# LFMXO5_25 register map
Vendor: Latticsemi.com; Series: LFMXO5; File version: 1.0
Registers are 32-bit, read-write, reset 0x0 unless marked. A register's access mark holds for its fields unless they carry their own. Offsets are from the block's base; [hi:lo] are bit positions; {n}, {i} and the like mark numbered series.

## i3c_m_inst (part 1 of 2)
Base 0x00010400
0x04 CLKDIV — System Clock Divider Register
  [7:0] sys_clk_div — Indicates the clock pulse width of the generated SCL in terms of number of system clock (clk_i) cycles
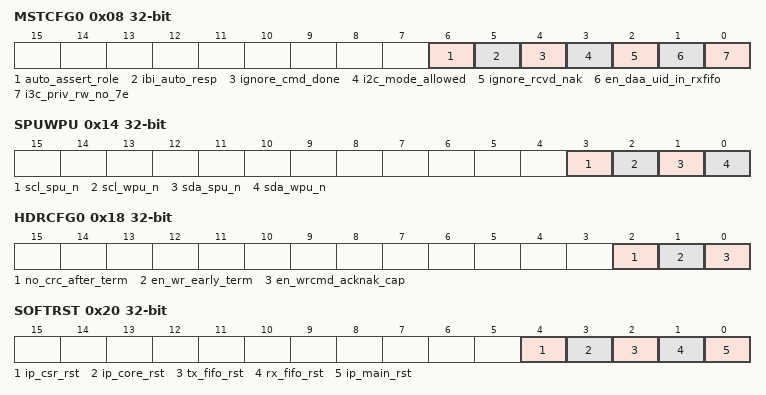
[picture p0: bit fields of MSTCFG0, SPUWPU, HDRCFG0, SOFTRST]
0x08 MSTCFG0 — Controller Configuration 0 Register
  [6] auto_assert_role — Applicable only when Secondary Controller is enabled. 1 - Enable auto assert role. Automatically assert role when taking over as the new Active Controller after GETACCCR CCC. The device will send the broadcast address {0x7E, W} to assert its role. 0 - Disable auto assert role. Device will wait until other device pull the SDA down or if user writes to Tx FIFO.
  [5] ibi_auto_resp — Applicable only when Secondary Controller is enabled. 1 - Always NAK the IBI request and continue the current transfer until Tx FIFO is empty. 0 - Pause the SCL on low during ACK phase and wait for the user to program the appropriate response. See registers ibi_rcnt and ibi_resp.
  [4] ignore_cmd_done — 1 - The I3C controller will continue to process the contents of the Tx FIFO until it is empty. 0 - The I3C controller will stop after transferring 1 packet and the user will have to set/program the start register again to resume the transfer.
  [3] i2c_mode_allowed — 1 - Allows transferring I2C frames. 0 - Only I3C frames can be transferred.
  [2] ignore_rcvd_nak — 1 - The IP will continue to process the contents of the Tx FIFO (until empty) even if a NAK was received. 0 - The I3C controller will stop after receiving a NAK and the user will have to set/program the start register again to resume the transfer.
  [1] en_daa_uid_in_rxfifo — During dynamic address assignment, the I3C targets will broadcast their unique IDs (48bits) including BCR and DCR as part of the arbitration process. 1 - The unique IDs, BCR, and DCR will be stored in Rx FIFO and can be read by user. 0 - It will be discarded.
  [0] i3c_priv_rw_no_7e — 1 - Starts the private write/read access with dynamic address instead of I3C broadcast address 0x7E. 0 - The private access will start with 0x7E address followed by repeated start (Sr) then the target's dynamic address.
0x0C ODTIMER — Open-Drain Timer.
  [3:0] od_timer — Used for generation of SCL clock in open drain mode of I3C transaction. This setting indicates the clock pulse width of open drain SCL clock in terms of number of normal SCL clock cycles as generated using sys_clk_div setting. (0 - 1 SCL clock cycle. Use normal SCL clock generated using the System Clock divider., 1 - 2 SCL clock cycles, ..., 15 - 16 SCL clock cycles)
0x10 I2C_DIV — I2C Clock Divider Register. Applicable only when user enabled the use of internal dividers in IP Generation GUI.
  [7:0] i2c_clkdiv — Used for generation of SCL clock in I2C mode. This setting indicates the clock pulse width of SCL in terms of number of system clock (clk_i) cycles. (0 - 1 clk_i clock cycle, 1 - 2 clk_i clock cycles, ..., 255 - 256 clk_i clock cycles)
0x14 SPUWPU — Pull Up Resistor Disable Register
  [3] scl_spu_n — When set to high, disables the strong pull up resistor in SCL.
  [2] scl_wpu_n — When set to high, disables the weak pull up resistor in SCL.
  [1] sda_spu_n — When set to high, disables the strong pull up resistor in SDA.
  [0] sda_wpu_n — When set to high, disables the weak pull up resistor in SDA.
0x18 HDRCFG0 — HDR-DDR Mode Configuration. Applicable only when user enabled the HDR-DDR capability.
  [2] no_crc_after_term — Applicable only when HDR-DDR capability is enabled. Configures the data transfer ending procedure. 1 - No CRC word follows early termination request. 0 - CRC word follows early termination request.
  [1] en_wr_early_term — Applicable only when HDR-DDR capability is enabled. Configures the data transfer ending procedure. 1 - Enables write early termination request. 0 - Disables write early termination request.
  [0] en_wrcmd_acknak_cap — Applicable only when HDR-DDR capability is enabled. Configures the data transfer ending procedure. 1 - Enables ACK/NAK capability for write command. 0 - Disables ACK/NAK capability for write command.
0x20 SOFTRST — Soft Reset.
  [4] ip_csr_rst — When set to high, resets the IP registers only. Auto-clear.
  [3] ip_core_rst — When set to high, resets the I3C Controller only. Auto-clear.
  [2] tx_fifo_rst — When set to high, resets the Tx FIFO only. Auto-clear.
  [1] rx_fifo_rst — When set to high, resets the Rx FIFO only. Auto-clear.
  [0] ip_main_rst — When set to high, resets the whole IP including registers and FIFO. Auto-clear.
0x44 TXSTART — Transmit Start Register
  [0] tx_start — When set to high, the IP starts processing the contents of Tx FIFO. This register auto-clears when when a command is done or a NAK is received unless it is bypassed by ignore_cmd_done or ignore_rcvd_nak register setting in controller configuration 0 register. To continue with the transfer, user will have to set this to 1 again.
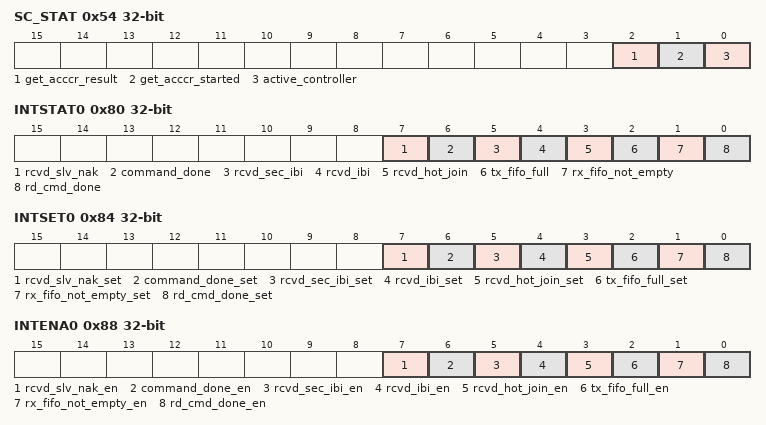
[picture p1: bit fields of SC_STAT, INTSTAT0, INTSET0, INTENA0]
0x54 SC_STAT ro — Secondary Controller Status Info Register. Applicable only when user enabled the Secondary Controller in IP Generation GUI.
  [2] get_acccr_result — This status is the result of the GETACCCR command. This information is valid only if the interrupt status register get_acccr_done is asserted. Clear when interrupt status get_acccr_done is cleared. (0 - Successful controller handoff, 1 - ControllerHandoff failed)
  [1] get_acccr_started — Indicates that the device has started/sent GETACCCR CCC. Clear when interrupt status get_acccr_done is cleared. 1 - Started GETACCCR CCC, 0 - No GETACCCR CCC
  [0] active_controller — Indicates the current role of this device. The default value of this register takes the Device Role GUI parameter setting. If user selected Primary Controller, then the default value will be (1) Active Controller, otherwise it will be acting as a Target (0). The value of this register may change if there is a successful controller handoff or if user forced it by programming the Set Device Role register. 1 - Active Controller 0 - Target
0x58 SC_ROLE ro — Set Device Role register. Applicable only when user enabled the Secondary Controller in IP Generation GUI.
  [2] set_device_role — This status is the result of the GETACCCR command. This information is valid only if the interrupt status register get_acccr_done is asserted. Clear when interrupt status get_acccr_done is cleared. (0 - Successful controller handoff, 1 - ControllerHandoff failed)
0x5C SC_TIMER0 — Secondary Controller Timeout Register. Applicable only when user enabled the Secondary Controller in IP Generation GUI.
  [7:0] crh_timeout0 — Controller role handoff timeout value. This is the number of system clock (clk_i) cycles. The default value is equivalent to 100us (40ns * 2500). This timeout value is used during controller handoff procedure when the former active controller confirms if the new active controller will assert its controller role.
0x60 SC_TIMER1 — Secondary Controller Timeout Register. Applicable only when user enabled the Secondary Controller in IP Generation GUI.
  [7:0] crh_timeout1 — Controller role handoff timeout value. This is the number of system clock (clk_i) cycles. The default value is equivalent to 100us (40ns * 2500). This timeout value is used during controller handoff procedure when the former active controller confirms if the new active controller will assert its controller role.
0x64 SC_TIMER2 — Secondary Controller Timeout Register. Applicable only when user enabled the Secondary Controller in IP Generation GUI.
  [3:0] crh_timeout2 — Controller role handoff timeout value. This is the number of system clock (clk_i) cycles. The default value is equivalent to 100us (40ns * 2500). This timeout value is used during controller handoff procedure when the former active controller confirms if the new active controller will assert its controller role.
0x70 DA_ACKED — Dynamic Address ACKed Counter.
  [7:0] num_da_acked — Running counter that indicates the number of dynamic address that was acknowledged during Enter DAA command. This counter will reset to 0 after writing all 1's.
0x74 IBIRCNT — IBI Read Count Register. Applicable only when in-band interrupt capability is enabled.
  [7:0] ibi_rcnt — Indicates the number of bytes to read from target during IBI. This should be set depending on the target's setting. Set this register to 0 when responding to Hot Join or Secondary Controller interrupt.
0x78 IBIRESP — IBI Response Register. Applicable only when in-band interrupt capability is enabled.
  [0] ibi_resp — This will be the response of the I3C controller to the IBI or Hot Join request. Write to this register will trigger the IP to send the indicated response. 0 - ACK the IBI or Hot Join, 1 - NAK the IBI or Hot Join
0x7C IBIADDR ro — IBI Address Register. Applicable only when in-band interrupt capability is enabled.
  [7:1] ibi_addr — This shows the address of the I3C Target or Secondary Controller that requested the IBI. If the interrupt is Hot Join, this will show the reserved target address 7'h02.
0x80 INTSTAT0 — Interrupt Status 0 Register. When high, it indicates an event and when the corresponding interrupt enable bit is enabled, it will cause the assertion of interrupt port (int_o).
  [7] rcvd_slv_nak — When set to high, it indicates that a NAK was received. Clear on write of 1.
  [6] command_done — When set to high, it indicates that a command has been sent (Private Write/Read or CCC). Clear on write of 1.
  [5] rcvd_sec_ibi — When set, it indicates that Secondary Controller interrupt is received. Clear on write of 1.
  [4] rcvd_ibi — When set, it indicates that In-band interrupt is received. Clear on write of 1.
  [3] rcvd_hot_join — When set to high, it indicates that Hot Join interrupt is received. Clear on write of 1.
  [2] tx_fifo_full — When set to high, it indicates that Tx FIFO is full. Clear on write of 1.
  [1] rx_fifo_not_empty — When set to high, it indicates that Rx FIFO is not empty. Clear on write of 1.
  [0] rd_cmd_done — When set to high, it indicates that a private read is done and all requested data specified by length are available in the Rx FIFO. Clear on write of 1.
0x84 INTSET0 wo — Interrupt Set 0 Register. This is a dummy register that is used to test the assertion of interrupt status. When set to high, it triggers the corresponding interrupt status 0 signal.
  [7] rcvd_slv_nak_set — When set to high, it triggers the corresponding interrupt status 0 signal.
  [6] command_done_set — When set to high, it triggers the corresponding interrupt status 0 signal.
  [5] rcvd_sec_ibi_set — When set to high, it triggers the corresponding interrupt status 0 signal.
  [4] rcvd_ibi_set — When set to high, it triggers the corresponding interrupt status 0 signal.
  [3] rcvd_hot_join_set — When set to high, it triggers the corresponding interrupt status 0 signal.
  [2] tx_fifo_full_set — When set to high, it triggers the corresponding interrupt status 0 signal.
  [1] rx_fifo_not_empty_set — When set to high, it triggers the corresponding interrupt status 0 signal.
  [0] rd_cmd_done_set — When set to high, it triggers the corresponding interrupt status 0 signal.
0x88 INTENA0 — Interrupt Enable 0 Register. When set to high, it enables the corresponding interrupt status 0 signal to cause the assertion of interrupt port signal (int_o).
  [7] rcvd_slv_nak_en — When set to high, it enables the corresponding interrupt status 0 signal to cause the assertion of interrupt port signal (int_o).
  [6] command_done_en — When set to high, it enables the corresponding interrupt status 0 signal to cause the assertion of interrupt port signal (int_o).
  [5] rcvd_sec_ibi_en — When set to high, it enables the corresponding interrupt status 0 signal to cause the assertion of interrupt port signal (int_o).
  [4] rcvd_ibi_en — When set to high, it enables the corresponding interrupt status 0 signal to cause the assertion of interrupt port signal (int_o).
  [3] rcvd_hot_join_en — When set to high, it enables the corresponding interrupt status 0 signal to cause the assertion of interrupt port signal (int_o).
  [2] tx_fifo_full_en — When set to high, it enables the corresponding interrupt status 0 signal to cause the assertion of interrupt port signal (int_o).
  [1] rx_fifo_not_empty_en — When set to high, it enables the corresponding interrupt status 0 signal to cause the assertion of interrupt port signal (int_o).
  [0] rd_cmd_done_en — When set to high, it enables the corresponding interrupt status 0 signal to cause the assertion of interrupt port signal (int_o).
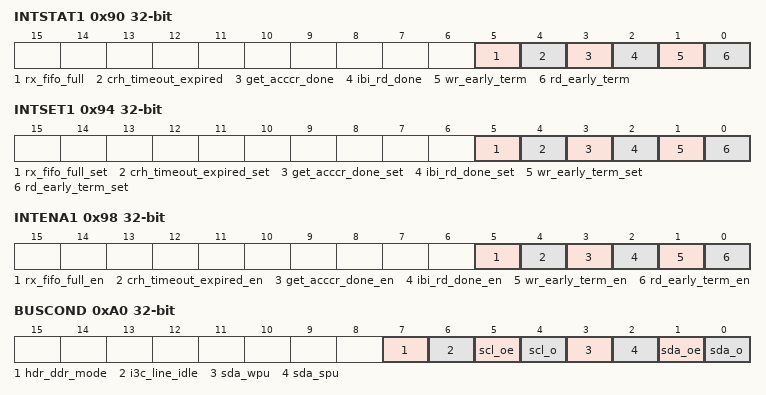
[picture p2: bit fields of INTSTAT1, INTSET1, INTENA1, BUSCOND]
0x90 INTSTAT1 — Interrupt Status 1 Register. When high, it indicates an event and when the corresponding interrupt enable bit is enabled, it will cause the assertion of interrupt port (int_o).
  [5] rx_fifo_full — When set to high, it indicates that Rx FIFO is full. Clear on write of 1.
  [4] crh_timeout_expired — Applicable only when user enabled the Secondary Controller in IP Generation GUI. When set to high, it indicates that the controller handoff has failed due to the new controller failing to assert its role within the specified timeout value in Secondary Controller Timeout register. This means that this device will remain as active controller. Clear on write of 1.
  [3] get_acccr_done — Applicable only when user enabled the Secondary Controller in IP Generation GUI. When set to high, it indicates that GETACCCR CCC was done and the result of this command is available in the secondary controller status info register. Clear on write of 1.
  [2] ibi_rd_done — When set to high, it indicates IBI payload was received and IBI read transaction has been terminated. Clear on write of 1.
  [1] wr_early_term — When set to high, it indicates that I2C private write data was not completely transferred due to the target terminating it with NAK. Clear on write of 1.
  [0] rd_early_term — When set to high, it indicates that a private read is done due to target terminating with T bit==0 and the read data received is less than what was requested. Clear on write of 1.
0x94 INTSET1 wo — Interrupt Set 1 Register. This is a dummy register that is used to test the assertion of interrupt status. When set to high, it triggers the corresponding interrupt status 1 signal.
  [5] rx_fifo_full_set — When set to high, it triggers the corresponding interrupt status 1 signal.
  [4] crh_timeout_expired_set — When set to high, it triggers the corresponding interrupt status 1 signal.
  [3] get_acccr_done_set — When set to high, it triggers the corresponding interrupt status 1 signal.
  [2] ibi_rd_done_set — When set to high, it triggers the corresponding interrupt status 1 signal.
  [1] wr_early_term_set — When set to high, it triggers the corresponding interrupt status 1 signal.
  [0] rd_early_term_set — When set to high, it triggers the corresponding interrupt status 1 signal.
0x98 INTENA1 — Interrupt Enable 1 Register.When set to high, it enables the corresponding interrupt status 0 signal to cause the assertion of interrupt port signal (int_o).
  [5] rx_fifo_full_en — When set to high, it enables the corresponding interrupt status 0 signal to cause the assertion of interrupt port signal (int_o).
  [4] crh_timeout_expired_en — When set to high, it enables the corresponding interrupt status 0 signal to cause the assertion of interrupt port signal (int_o).
  [3] get_acccr_done_en — When set to high, it enables the corresponding interrupt status 0 signal to cause the assertion of interrupt port signal (int_o).
  [2] ibi_rd_done_en — When set to high, it enables the corresponding interrupt status 0 signal to cause the assertion of interrupt port signal (int_o).
  [1] wr_early_term_en — When set to high, it enables the corresponding interrupt status 0 signal to cause the assertion of interrupt port signal (int_o).
  [0] rd_early_term_en — When set to high, it enables the corresponding interrupt status 0 signal to cause the assertion of interrupt port signal (int_o).
0xA0 BUSCOND ro — Bus Condition Debug Register
  [7] hdr_ddr_mode — When high, indicates that the bus is currently in HDR-DDR mode. Otherwise it is in SDR mode.
  [6] i3c_line_idle — When high, indicates that the bus state is in idle. This also implies that bus is free (SCL and SDA are both high).
  [5] scl_oe — Shows the current value of the SCL output enable. 1 - SCL output is driven, 0 - SCL output is not driven
  [4] scl_o — Shows the current value of the SCL output generated by IP. 1 - SCL output is driven, 0 - SCL output is not driven
  [3] sda_wpu — Shows the current value of the SDA weak pull up control signal. 1 - weak pull up resistor is disabled, 0 - weak pull up resistor is enabled
  [2] sda_spu — Shows the current value of the SDA strong pull up control signal. 1 - strong pull up resistor is disabled, 0 - strong pull up resistor is enabled
  [1] sda_oe — Shows the current value of the SDA output enable. 1 - SDA output is driven, 0 - SDA output is not driven
  [0] sda_o — Shows the current value of the SDA output generated by IP.
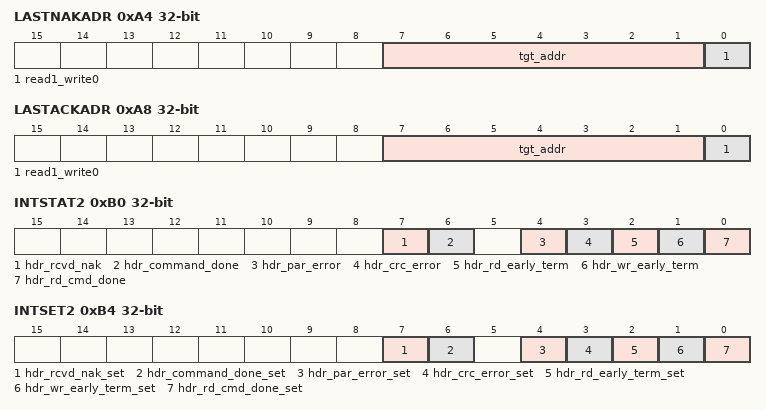
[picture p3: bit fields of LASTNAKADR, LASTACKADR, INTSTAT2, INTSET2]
0xA4 LASTNAKADR — Last NAKed Target Address
  [7:1] tgt_addr — This shows the latest target address driven by the I3C Controller that receives a NAK response.
  [0] read1_write0 — Indicates the transaction type either read (1) or write (0).
0xA8 LASTACKADR — Last ACKed Target Address
  [7:1] tgt_addr — This shows the latest target address driven by the I3C Controller that receives an ACK response.
  [0] read1_write0 — Indicates the transaction type either read (1) or write (0).
0xB0 INTSTAT2 — Interrupt Status 2 Register. When high, it indicates an event and when the corresponding interrupt enable bit is enabled, it will cause the assertion of interrupt port (int_o).
  [7] hdr_rcvd_nak — Applicable only if HDR-DDR capable. When set to high, it indicates that a NAK was received. Clear on write of 1.
  [6] hdr_command_done — Applicable only if HDR-DDR capable. When set to high, it indicates that a command has been sent (HDR Write/Read or CCC). Clear on write of 1.
  [4] hdr_par_error — Applicable only if HDR-DDR capable. When set, it indicates that Parity error is detected. Clear on write of 1.
  [3] hdr_crc_error — Applicable only if HDR-DDR capable. When set, it indicates that CRC error is detected. Clear on write of 1.
  [2] hdr_rd_early_term — Applicable only if HDR-DDR capable. When set to high, it indicates that HDR read is done due to target terminating the transfer and the read data received is less than what was requested. Clear on write of 1.
  [1] hdr_wr_early_term — Applicable only if HDR-DDR capable. When set to high, it indicates that HDR write data was not completely transferred due to the target terminating the transfer. Clear on write of 1.
  [0] hdr_rd_cmd_done — Applicable only if HDR-DDR capable. When set to high, it indicates that HDR read command is done and all requested data specified by length are available in the Rx FIFO. Clear on write of 1.
0xB4 INTSET2 wo — Interrupt Set 2 Register. This is a dummy register that is used to test the assertion of interrupt status. When set to high, it triggers the corresponding interrupt status 2 signal.
  [7] hdr_rcvd_nak_set — When set to high, it triggers the corresponding interrupt status 2 signal.
  [6] hdr_command_done_set — When set to high, it triggers the corresponding interrupt status 2 signal.
  [4] hdr_par_error_set — When set to high, it triggers the corresponding interrupt status 2 signal.
  [3] hdr_crc_error_set — When set to high, it triggers the corresponding interrupt status 2 signal.
  [2] hdr_rd_early_term_set — When set to high, it triggers the corresponding interrupt status 2 signal.
  [1] hdr_wr_early_term_set — When set to high, it triggers the corresponding interrupt status 2 signal.
  [0] hdr_rd_cmd_done_set — When set to high, it triggers the corresponding interrupt status 2 signal.
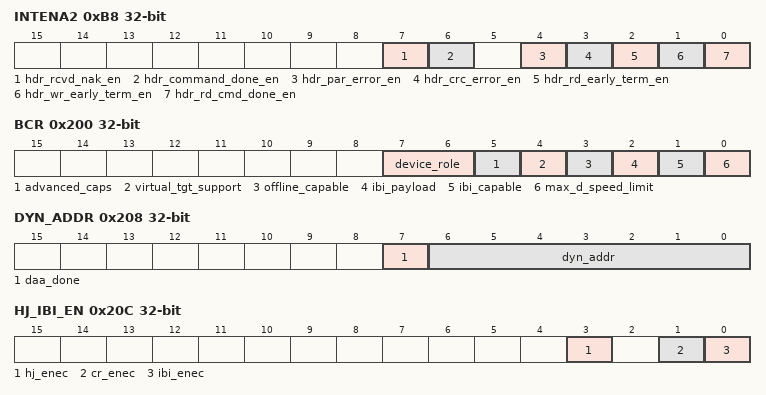
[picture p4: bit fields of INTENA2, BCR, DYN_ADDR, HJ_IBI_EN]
0xB8 INTENA2 — Interrupt Enable 2 Register. When set to high, it enables the corresponding interrupt status 2 signal to cause the assertion of interrupt port signal (int_o).
  [7] hdr_rcvd_nak_en — When set to high, it enables the corresponding interrupt status 2 signal to cause the assertion of interrupt port signal (int_o).
  [6] hdr_command_done_en — When set to high, it enables the corresponding interrupt status 2 signal to cause the assertion of interrupt port signal (int_o).
  [4] hdr_par_error_en — When set to high, it enables the corresponding interrupt status 2 signal to cause the assertion of interrupt port signal (int_o).
  [3] hdr_crc_error_en — When set to high, it enables the corresponding interrupt status 2 signal to cause the assertion of interrupt port signal (int_o).
  [2] hdr_rd_early_term_en — When set to high, it enables the corresponding interrupt status 2 signal to cause the assertion of interrupt port signal (int_o).
  [1] hdr_wr_early_term_en — When set to high, it enables the corresponding interrupt status 2 signal to cause the assertion of interrupt port signal (int_o).
  [0] hdr_rd_cmd_done_en — When set to high, it enables the corresponding interrupt status 2 signal to cause the assertion of interrupt port signal (int_o).
0xC0 TXFIFO — Tx FIFO Access
  [7:0] tx_fifo_data — This is a dummy register that is used to fill data to Tx FIFO. User will use this to send the packet frames to Tx FIFO through repeated write access to this dummy register. Reading this register would return the status of Tx FIFO not_empty flag.
0x100 RXFIFO ro — Rx FIFO Access
  [7:0] rx_fifo_data — This is a dummy register that is used to get the read data from Rx FIFO. The read data as a result of response from read request will be stored in Rx FIFO. User will use this to get the received data from Rx FIFO through repeated read access to this dummy register. User may want to check the interrupt status 0 register (bit[1]) first to determine if Rx FIFO is not empty.
0x200 BCR ro — Target Bus Characteristics Register
  [7:6] device_role — 2'b00 - I3C Target, 2'b01 - I3C Controller-capable (Not implemented in this IP), Others - Reserved for future definition by MIPI Alliance I3C WG
  [5] advanced_caps — 0 - Does not support optional advanced capabilities., 1 - Supports optional advanced capabilities. When Target is configured with IBI capability and IBI payload, this is set to 1 for optional Pending Read MDB support.
  [4] virtual_tgt_support — 0 - Is not a Virtual Target and does not expose other downstream Device(s), 1 - Is a Virtual Target, or exposes other downstream Device(s)
  [3] offline_capable — 0 - Device will always respond to I3C Bus commands, 1 - Device will not always respond to I3C Bus Commands
  [2] ibi_payload — From IBI Payload Size attiribute. 0 - If IBI Payload Size attribute is set to 0. No data bytes follow the IBI., 1 - If IBI Payload Size attribute is set to greater than or equal to 1. One data byte (MDB) shall follow the accepted IBI, and additional data bytes may follow
  [1] ibi_capable — From IBI Capable attribute. 0 - Not capable., 1 - Capable.
  [0] max_d_speed_limit — From Maximum Data Speed Limitation attribute. 0 - No limitation., 1 - With limitation. Controller shall use GETMXDS CCC to get specific limitation from Target.
0x204 DCR ro — Target Device Characteristics Register
  [7:0] dcr — Device ID set by User through DCR attribute. 255 available codes for describing the type of sensor or Device (e.g., accelerometer, gyroscope, composite Devices). Default value is 8'b0 for generic Device.
0x208 DYN_ADDR ro — Assigned dynamic address and done flag
  [7] daa_done — 0 - DA is not yet assigned or is reset by RSTDAA CCC.,1 - DA is assigned via ENTDAA, SETNEWDA, SETAASA or SETDASA CCC
  [6:0] dyn_addr — Dynamic Address Assigned to I3C Target
0x20C HJ_IBI_EN ro — Hot-Join and IBI enable from Controller via ENEC/DISEC CCC
  [3] hj_enec — Hot-Join Enable by Controller. 0 - Target-initiated Hot-Join is not allowed on the I3C bus, 1 - Target-initiated Hot-Join is allowed on the I3C bus
  [1] cr_enec — Controller Role Request Enable by Controller. 0 - Target-initiated Controller Role Request is not allowed on the I3C bus, 1 - Target-initiated Controller Role Request is allowed on the I3C bus
  [0] ibi_enec — IBI Enable by Controller. 0 - Target-initiated interrupts are not allowed on the I3C bus, 1 - Target-initiated interrupts are allowed on the I3C bus
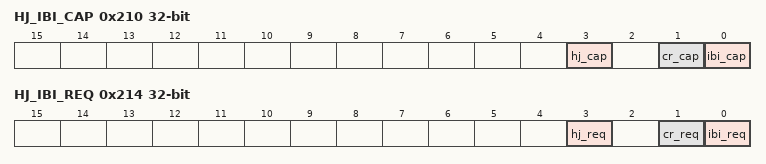
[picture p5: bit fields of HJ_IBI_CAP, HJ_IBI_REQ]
0x210 HJ_IBI_CAP ro — Hot-Join and IBI capability configured by User using attributes
  [3] hj_cap — 0 - Target device is configured without Hot-Join Capability, 1 - Target device is configured with Hot-Join Capability
  [1] cr_cap — 0 - Target device is configured without Secondary-Controller Capability, 1 - Target device is configured with Secondary-Controller Capability
  [0] ibi_cap — 0 - Target device is configured without IBI Capability, 1 - Target device is configured with IBI Capability
0x214 HJ_IBI_REQ — Hot-Join and IBI request from User.
  [3] hj_req — When set to High, Target will initiate Hot-Join request at the next valid opportunity. Reset to 0 when Hot-Join is done or disabled by the Controller.
  [1] cr_req — When set to High, Target will initiate Controller Role Request at the next valid opportunity. Reset to 0 when Controller Role Request is done or disabled by the Controller.
  [0] ibi_req — When set to High, Target will initiate IBI at the next valid opportunity. Reset to 0 when IBI is done or disabled by the Controller.
0x218 HJ_IBI_RETRY — Number of retries for Hot-Join and IBI.
  [7:0] hj_ibi_retry — Indicates number of times the Target retries Hot-Join or IBI when it is NACKed by the Controller. When set to 0, number of tries is not limited.
0x21C MWL_MSB ro — Most significant byte of Maximum Write Length set by the Controller
  [7:0] mwl_msb — Most Significant Byte of maximum write length set by I3C Controller via SETMWL CCC. If SETMWL is greater than default value 512 (FIFO size), MWL will be set to 512.
0x220 MWL_LSB ro — Least significant byte of Maximum Write Length set by the Controller
  [7:0] mwl_lsb — Least Significant Byte of maximum write length set by I3C Controller via SETMWL CCC. If SETMWL is greater than default value 512 (FIFO size), MWL will be set to 512.
0x224 MRL_MSB ro — Most significant byte of Maximum Read Length set by the Controller
  [7:0] mrl_msb — Most Significant Byte of maximum read length set by I3C Controller via SETMRL CCC. If SETMRL is greater than default value 512 (FIFO size), MRL will be set to 512.
0x228 MRL_LSB ro — Least significant byte of Maximum Read Length set by the Controller
  [7:0] mrl_lsb — Least Significant Byte of maximum read length set by I3C Controller via SETMRL CCC. If SETMRL is greater than default value 512 (FIFO size), MRL will be set to 512.
